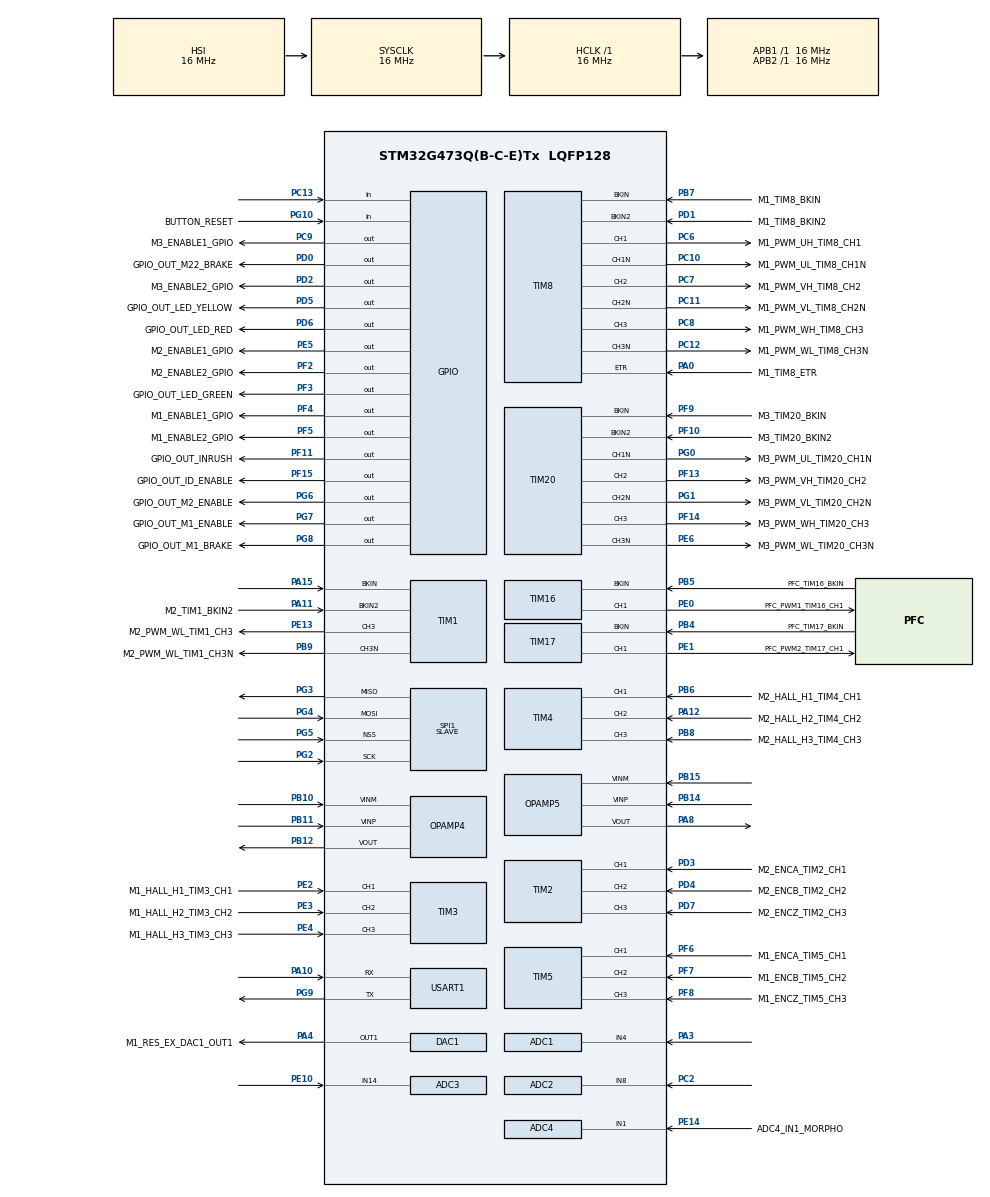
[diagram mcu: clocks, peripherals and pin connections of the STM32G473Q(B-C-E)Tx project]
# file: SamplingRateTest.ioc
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ADC1.Channel-0\#ChannelRegularConversion=ADC_CHANNEL_4
ADC1.ClockPrescaler=ADC_CLOCK_SYNC_PCLK_DIV1
ADC1.ContinuousConvMode=DISABLE
ADC1.DMAAccessModeView=ENABLE
ADC1.DMAContinuousRequests=DISABLE
ADC1.Mode=ADC_DUALMODE_REGSIMULT
ADC1.NbrOfConversionFlag=1
ADC1.OffsetNumber-0\#ChannelRegularConversion=ADC_OFFSET_NONE
ADC1.Rank-0\#ChannelRegularConversion=1
ADC1.SamplingTime-0\#ChannelRegularConversion=ADC_SAMPLETIME_2CYCLES_5
ADC1.TwoSamplingDelay=ADC_TWOSAMPLINGDELAY_12CYCLES
ADC1.master=1
ADC2.Channel-1\#ChannelRegularConversion=ADC_CHANNEL_8
ADC2.ClockPrescaler=ADC_CLOCK_SYNC_PCLK_DIV1
ADC2.ContinuousConvMode=DISABLE
ADC2.DMAAccessModeView=ENABLE
ADC2.DMAContinuousRequests=DISABLE
ADC2.EnableAnalogWatchDog3=false
ADC2.Mode=ADC_DUALMODE_REGSIMULT
ADC2.NbrOfConversion=1
ADC2.NbrOfConversionFlag=1
ADC2.OffsetNumber-1\#ChannelRegularConversion=ADC_OFFSET_NONE
ADC2.Overrun=ADC_OVR_DATA_PRESERVED
ADC2.Rank-1\#ChannelRegularConversion=1
ADC2.Resolution=ADC_RESOLUTION_12B
ADC2.SamplingTime-1\#ChannelRegularConversion=ADC_SAMPLETIME_2CYCLES_5
ADC2.TwoSamplingDelay=ADC_TWOSAMPLINGDELAY_12CYCLES
ADC3.Channel-2\#ChannelRegularConversion=ADC_CHANNEL_14
ADC3.ClockPrescaler=ADC_CLOCK_ASYNC_DIV64
ADC3.ContinuousConvMode=DISABLE
ADC3.DMAAccessModeView=ENABLE
ADC3.DMAContinuousRequests=DISABLE
ADC3.Mode=ADC_DUALMODE_REGSIMULT
ADC3.NbrOfConversionFlag=1
ADC3.OffsetNumber-2\#ChannelRegularConversion=ADC_OFFSET_NONE
ADC3.Rank-2\#ChannelRegularConversion=1
ADC3.SamplingTime-2\#ChannelRegularConversion=ADC_SAMPLETIME_2CYCLES_5
ADC3.TwoSamplingDelay=ADC_TWOSAMPLINGDELAY_12CYCLES
ADC3.master=1
ADC4.Channel-1\#ChannelRegularConversion=ADC_CHANNEL_1
ADC4.ClockPrescaler=ADC_CLOCK_ASYNC_DIV64
ADC4.DMAAccessModeView=ENABLE
ADC4.Mode=ADC_DUALMODE_REGSIMULT
ADC4.NbrOfConversionFlag=1
ADC4.OffsetNumber-1\#ChannelRegularConversion=ADC_OFFSET_NONE
ADC4.Rank-1\#ChannelRegularConversion=1
ADC4.SamplingTime-1\#ChannelRegularConversion=ADC_SAMPLETIME_2CYCLES_5
ADC4.TwoSamplingDelay=ADC_TWOSAMPLINGDELAY_12CYCLES
DAC1.DAC_Channel-DAC_OUT2_ExtAndInt=DAC_CHANNEL_2
Mcu.Family=STM32G4
Mcu.Name=STM32G473Q(B-C-E)Tx
Mcu.Package=LQFP128
NVIC.ADC1_2_IRQn=true\:1\:0\:true\:false\:true\:true\:true\:true
NVIC.PriorityGroup=NVIC_PRIORITYGROUP_4
PA0.GPIO_Label=M1_TIM8_ETR
PA0.Signal=S_TIM8_ETR
PA10.Mode=Asynchronous
PA10.Signal=USART1_RX
PA11.GPIO_Label=M2_TIM1_BKIN2
PA11.Mode=Activate-Break-Input-2
PA11.Signal=TIM1_BKIN2
PA12.GPIO_Label=M2_HALL_H2_TIM4_CH2
PA12.Signal=S_TIM4_CH2
PA13.Mode=Trace_Asynchronous_SW
PA13.Signal=SYS_JTMS-SWDIO
PA14.Mode=Trace_Asynchronous_SW
PA14.Signal=SYS_JTCK-SWCLK
PA15.Mode=Activate-Break-Input
PA15.Signal=TIM1_BKIN
PA2.GPIO_Mode=GPIO_MODE_ANALOG
PA2.GPIO_PuPd=GPIO_NOPULL
PA2.Signal=ADC1_IN3
PA3.Mode=IN4-Single-Ended
PA3.Signal=ADC1_IN4
PA4.GPIO_Label=M1_RES_EX_DAC1_OUT1
PA4.Signal=COMP_DAC11_group
PA6.GPIO_Label=M3_TEMP_ID_ADC2IN3
PA6.Signal=ADC2_IN3
PA8.Mode=Standalone
PA8.Signal=OPAMP5_VOUT
PB0.Signal=OPAMP3_VINP
PB1.Signal=OPAMP3_VOUT
PB10.Mode=Standalone
PB10.Signal=OPAMP4_VINM
PB11.Mode=Standalone
PB11.Signal=OPAMP4_VINP
PB12.Mode=Standalone
PB12.Signal=OPAMP4_VOUT
PB13.GPIO_Label=M1_VBUS_ADC3_IN5
PB13.Signal=ADC3_IN5
PB14.Mode=Standalone
PB14.Signal=OPAMP5_VINP
PB15.Mode=Standalone
PB15.Signal=OPAMP5_VINM
PB3.Mode=Trace_Asynchronous_SW
PB3.Signal=SYS_JTDO-SWO
PB4.GPIO_Label=PFC_TIM17_BKIN
PB4.Mode=Activate-Break-Input
PB4.Signal=TIM17_BKIN
PB5.GPIO_Label=PFC_TIM16_BKIN
PB5.Mode=Activate-Break-Input
PB5.Signal=TIM16_BKIN
PB6.GPIO_Label=M2_HALL_H1_TIM4_CH1
PB6.Signal=S_TIM4_CH1
PB7.GPIO_Label=M1_TIM8_BKIN
PB7.Mode=Activate-Break-Input
PB7.Signal=TIM8_BKIN
PB8-BOOT0.GPIO_Label=M2_HALL_H3_TIM4_CH3
PB8-BOOT0.Signal=S_TIM4_CH3
PB9.GPIO_Label=M2_PWM_WL_TIM1_CH3N
PB9.Mode=PWM Generation3 CH3 CH3N
PB9.Signal=TIM1_CH3N
PC0.Signal=ADC2_IN6
PC10.GPIO_Label=M1_PWM_UL_TIM8_CH1N
PC10.Mode=PWM Generation1 CH1 CH1N
PC10.Signal=TIM8_CH1N
PC11.GPIO_Label=M1_PWM_VL_TIM8_CH2N
PC11.Mode=Output Compare2 CH2 CH2N
PC11.Signal=TIM8_CH2N
PC12.GPIO_Label=M1_PWM_WL_TIM8_CH3N
PC12.Mode=Output Compare3 CH3 CH3N
PC12.Signal=TIM8_CH3N
PC13.GPIO_PuPd=GPIO_PULLUP
PC13.Signal=GPIO_Input
PC14-OSC32_IN.Mode=LSE-External-Oscillator
PC14-OSC32_IN.Signal=RCC_OSC32_IN
PC15-OSC32_OUT.Mode=LSE-External-Oscillator
PC15-OSC32_OUT.Signal=RCC_OSC32_OUT
PC2.GPIO_Mode=GPIO_MODE_ANALOG
PC2.GPIO_PuPd=GPIO_NOPULL
PC2.Mode=IN8-Single-Ended
PC2.Signal=ADC2_IN8
PC3.Signal=ADC2_IN9
PC4.GPIO_Label=M2_TEMP_ID_ADC2_IN5
PC4.Signal=ADC2_IN5
PC5.GPIO_Label=PFC_AC_ZC_ADC2_IN11
PC5.Signal=ADC2_IN11
PC6.GPIO_Label=M1_PWM_UH_TIM8_CH1
PC6.Signal=S_TIM8_CH1
PC7.GPIO_Label=M1_PWM_VH_TIM8_CH2
PC7.Signal=S_TIM8_CH2
PC8.GPIO_Label=M1_PWM_WH_TIM8_CH3
PC8.Signal=S_TIM8_CH3
PC9.GPIO_Label=M3_ENABLE1_GPIO
PC9.Signal=GPIO_Output
PD0.GPIO_Label=GPIO_OUT_M22_BRAKE
PD0.Signal=GPIO_Output
PD1.GPIO_Label=M1_TIM8_BKIN2
PD1.Mode=Activate-Break-Input-2
PD1.Signal=TIM8_BKIN2
PD2.GPIO_Label=M3_ENABLE2_GPIO
PD2.Signal=GPIO_Output
PD3.GPIO_Label=M2_ENCA_TIM2_CH1
PD3.Signal=S_TIM2_CH1
PD4.GPIO_Label=M2_ENCB_TIM2_CH2
PD4.Signal=S_TIM2_CH2
PD5.GPIO_Label=GPIO_OUT_LED_YELLOW
PD5.Signal=GPIO_Output
PD6.GPIO_Label=GPIO_OUT_LED_RED
PD6.Signal=GPIO_Output
PD7.GPIO_Label=M2_ENCZ_TIM2_CH3
PD7.Signal=S_TIM2_CH3
PE0.GPIO_Label=PFC_PWM1_TIM16_CH1
PE0.Signal=S_TIM16_CH1
PE1.GPIO_Label=PFC_PWM2_TIM17_CH1
PE1.Signal=S_TIM17_CH1
PE10.Mode=IN14-Single-Ended
PE10.Signal=ADC3_IN14
PE11.GPIO_Label=M2_PWM_VH_TIM1_CH2
PE11.Signal=S_TIM1_CH2
PE13.GPIO_Label=M2_PWM_WL_TIM1_CH3
PE13.Signal=S_TIM1_CH3
PE14.GPIO_Label=ADC4_IN1_MORPHO
PE14.Mode=IN1-Single-Ended
PE14.Signal=ADC4_IN1
PE15.GPIO_Label=M1_TEMP_ID_ADC4_IN2
PE15.Signal=ADC4_IN2
PE2.GPIO_Label=M1_HALL_H1_TIM3_CH1
PE2.Signal=S_TIM3_CH1
PE3.GPIO_Label=M1_HALL_H2_TIM3_CH2
PE3.Signal=S_TIM3_CH2
PE4.GPIO_Label=M1_HALL_H3_TIM3_CH3
PE4.Signal=S_TIM3_CH3
PE5.GPIO_Label=M2_ENABLE1_GPIO
PE5.Signal=GPIO_Output
PE6.GPIO_Label=M3_PWM_WL_TIM20_CH3N
PE6.Mode=Output Compare3 CH3 CH3N
PE6.Signal=TIM20_CH3N
PE9.GPIO_Label=M2_PWM_UH_TIM1_CH1
PE9.Signal=S_TIM1_CH1
PF0-OSC_IN.Mode=HSE-External-Clock-Source
PF0-OSC_IN.Signal=RCC_OSC_IN
PF1-OSC_OUT.GPIO_Label=ADC2_IN10_PFC_AC_V
PF1-OSC_OUT.Signal=ADC2_IN10
PF10.GPIO_Label=M3_TIM20_BKIN2
PF10.Mode=Activate-Break-Input-2
PF10.Signal=TIM20_BKIN2
PF11.GPIO_Label=GPIO_OUT_INRUSH
PF11.Signal=GPIO_Output
PF12.GPIO_Label=M3_PWM_UH_TIM20_CH1
PF12.Signal=S_TIM20_CH1
PF13.GPIO_Label=M3_PWM_VH_TIM20_CH2
PF13.Signal=S_TIM20_CH2
PF14.GPIO_Label=M3_PWM_WH_TIM20_CH3
PF14.Signal=S_TIM20_CH3
PF15.GPIO_Label=GPIO_OUT_ID_ENABLE
PF15.Signal=GPIO_Output
PF2.GPIO_Label=M2_ENABLE2_GPIO
PF2.Signal=GPIO_Output
PF3.GPIO_Label=GPIO_OUT_LED_GREEN
PF3.Signal=GPIO_Output
PF4.GPIO_Label=M1_ENABLE1_GPIO
PF4.Signal=GPIO_Output
PF5.GPIO_Label=M1_ENABLE2_GPIO
PF5.Signal=GPIO_Output
PF6.GPIO_Label=M1_ENCA_TIM5_CH1
PF6.Signal=S_TIM5_CH1
PF7.GPIO_Label=M1_ENCB_TIM5_CH2
PF7.Signal=S_TIM5_CH2
PF8.GPIO_Label=M1_ENCZ_TIM5_CH3
PF8.Signal=S_TIM5_CH3
PF9.GPIO_Label=M3_TIM20_BKIN
PF9.Mode=Activate-Break-Input
PF9.Signal=TIM20_BKIN
PG0.GPIO_Label=M3_PWM_UL_TIM20_CH1N
PG0.Mode=PWM Generation1 CH1 CH1N
PG0.Signal=TIM20_CH1N
PG1.GPIO_Label=M3_PWM_VL_TIM20_CH2N
PG1.Mode=PWM Generation2 CH2 CH2N
PG1.Signal=TIM20_CH2N
PG10-NRST.GPIO_Label=BUTTON_RESET
PG10-NRST.Signal=GPIO_Input
PG2.Mode=Full_Duplex_Slave
PG2.Signal=SPI1_SCK
PG3.Mode=Full_Duplex_Slave
PG3.Signal=SPI1_MISO
PG4.Mode=Full_Duplex_Slave
PG4.Signal=SPI1_MOSI
PG5.Mode=NSS_Signal_Hard_Input
PG5.Signal=SPI1_NSS
PG6.GPIO_Label=GPIO_OUT_M2_ENABLE
PG6.Signal=GPIO_Output
PG7.GPIO_Label=GPIO_OUT_M1_ENABLE
PG7.Signal=GPIO_Output
PG8.GPIO_Label=GPIO_OUT_M1_BRAKE
PG8.Signal=GPIO_Output
PG9.Mode=Asynchronous
PG9.Signal=USART1_TX
ProjectManager.HeapSize=0x200
ProjectManager.StackSize=0x400
ProjectManager.TargetToolchain=STM32CubeIDE
RCC.ADC12Freq_Value=16000000
RCC.ADC345Freq_Value=16000000
RCC.AHBFreq_Value=16000000
RCC.APB1Freq_Value=16000000
RCC.APB1TimFreq_Value=16000000
RCC.APB2Freq_Value=16000000
RCC.APB2TimFreq_Value=16000000
RCC.CortexFreq_Value=16000000
RCC.EXTERNAL_CLOCK_VALUE=12288000
RCC.HCLKFreq_Value=16000000
RCC.HSE_VALUE=8000000
RCC.HSI48_VALUE=48000000
RCC.HSI_VALUE=16000000
RCC.SYSCLKFreq_VALUE=16000000
RCC.USBFreq_Value=64000000
RCC.VCOOutputFreq_Value=128000000
SH.COMP_DAC11_group.0=DAC1_OUT1,DAC_OUT1_ExtAndInt
SH.S_TIM16_CH1.0=TIM16_CH1,Output Compare1 CH1
SH.S_TIM17_CH1.0=TIM17_CH1,Output Compare1 CH1
SH.S_TIM1_CH1.0=TIM1_CH1
SH.S_TIM1_CH2.0=TIM1_CH2
SH.S_TIM1_CH3.0=TIM1_CH3,PWM Generation3 CH3 CH3N
SH.S_TIM20_CH1.0=TIM20_CH1
SH.S_TIM20_CH2.0=TIM20_CH2,PWM Generation2 CH2 CH2N
SH.S_TIM20_CH3.0=TIM20_CH3,Output Compare3 CH3 CH3N
SH.S_TIM2_CH1.0=TIM2_CH1,Encoder_Interface
SH.S_TIM2_CH2.0=TIM2_CH2,Encoder_Interface
SH.S_TIM2_CH3.0=TIM2_CH3,Input_Capture3_from_TI3
SH.S_TIM3_CH1.0=TIM3_CH1,Xored_Inputs_Hall_Sensor_Interface
SH.S_TIM3_CH2.0=TIM3_CH2,Xored_Inputs_Hall_Sensor_Interface
SH.S_TIM3_CH3.0=TIM3_CH3,Xored_Inputs_Hall_Sensor_Interface
SH.S_TIM4_CH1.0=TIM4_CH1,Xored_Inputs_Hall_Sensor_Interface
SH.S_TIM4_CH2.0=TIM4_CH2,Xored_Inputs_Hall_Sensor_Interface
SH.S_TIM4_CH3.0=TIM4_CH3,Xored_Inputs_Hall_Sensor_Interface
SH.S_TIM5_CH1.0=TIM5_CH1,Encoder_Interface
SH.S_TIM5_CH2.0=TIM5_CH2,Encoder_Interface
SH.S_TIM5_CH3.0=TIM5_CH3,Input_Capture3_from_TI3
SH.S_TIM8_CH1.0=TIM8_CH1,PWM Generation1 CH1 CH1N
SH.S_TIM8_CH2.0=TIM8_CH2,Output Compare2 CH2 CH2N
SH.S_TIM8_CH3.0=TIM8_CH3,Output Compare3 CH3 CH3N
SH.S_TIM8_ETR.0=TIM8_ETR,ETR-as-clearing-source
SPI1.Direction=SPI_DIRECTION_2LINES
SPI1.Mode=SPI_MODE_SLAVE
SPI1.VirtualNSS=VM_NSSHARD
SPI1.VirtualType=VM_SLAVE
TIM1.Channel-PWM\ Generation3\ CH3\ CH3N=TIM_CHANNEL_3
TIM16.Channel=TIM_CHANNEL_1
TIM17.Channel=TIM_CHANNEL_1
TIM2.Channel-Input_Capture3_from_TI3=TIM_CHANNEL_3
TIM20.Channel-Output\ Compare3\ CH3\ CH3N=TIM_CHANNEL_3
TIM20.Channel-PWM\ Generation1\ CH1\ CH1N=TIM_CHANNEL_1
TIM20.Channel-PWM\ Generation2\ CH2\ CH2N=TIM_CHANNEL_2
TIM5.Channel-Input_Capture3_from_TI3=TIM_CHANNEL_3
TIM8.Channel-Output\ Compare2\ CH2\ CH2N=TIM_CHANNEL_2
TIM8.Channel-Output\ Compare3\ CH3\ CH3N=TIM_CHANNEL_3
TIM8.Channel-PWM\ Generation1\ CH1\ CH1N=TIM_CHANNEL_1
USART1.VirtualMode-Asynchronous=VM_ASYNC
VP_SYS_VS_DBSignals.Mode=DisableDeadBatterySignals
VP_TIM16_VS_ClockSourceINT.Mode=Enable_Timer
VP_TIM17_VS_ClockSourceINT.Mode=Enable_Timer
VP_TIM1_VS_ClockSourceITR.Mode=TriggerSource_ITR1
VP_TIM1_VS_ControllerModeTrigger.Mode=Trigger Mode
VP_TIM20_VS_ClockSourceITR.Mode=TriggerSource_ITR1
VP_TIM20_VS_ControllerModeTrigger.Mode=Trigger Mode
VP_TIM3_VS_ClockSourceINT.Mode=Internal
VP_TIM4_VS_ClockSourceINT.Mode=Internal
VP_TIM8_VS_ClockSourceITR.Mode=TriggerSource_ITR1
VP_TIM8_VS_ControllerModeTrigger.Mode=Trigger Mode
board=B-G473E-ZEST1S

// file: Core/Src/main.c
/* USER CODE BEGIN Header */
/**
  ******************************************************************************
  * @file           : main.c
  * @brief          : Main program body
  ******************************************************************************
  * @attention
  *
  * Copyright (c) 2025 STMicroelectronics.
  * All rights reserved.
  *
  * This software is licensed under terms that can be found in the LICENSE file
  * in the root directory of this software component.
  * If no LICENSE file comes with this software, it is provided AS-IS.
  *
  ******************************************************************************
  */
/* USER CODE END Header */
#include "main.h"
#include <string.h>
#include <stdio.h>

ADC_HandleTypeDef hadc1;
ADC_HandleTypeDef hadc2;
ADC_HandleTypeDef hadc3;
ADC_HandleTypeDef hadc4;

DAC_HandleTypeDef hdac1;

OPAMP_HandleTypeDef hopamp4;
OPAMP_HandleTypeDef hopamp5;

SPI_HandleTypeDef hspi1;

TIM_HandleTypeDef htim1;
TIM_HandleTypeDef htim2;
TIM_HandleTypeDef htim3;
TIM_HandleTypeDef htim4;
TIM_HandleTypeDef htim5;
TIM_HandleTypeDef htim8;
TIM_HandleTypeDef htim16;
TIM_HandleTypeDef htim17;
TIM_HandleTypeDef htim20;

UART_HandleTypeDef huart1;

void SystemClock_Config(void);
static void MX_GPIO_Init(void);
static void MX_ADC2_Init(void);
static void MX_DAC1_Init(void);
static void MX_OPAMP4_Init(void);
static void MX_OPAMP5_Init(void);
static void MX_SPI1_Init(void);
static void MX_TIM1_Init(void);
static void MX_TIM2_Init(void);
static void MX_TIM3_Init(void);
static void MX_TIM4_Init(void);
static void MX_TIM5_Init(void);
static void MX_TIM8_Init(void);
static void MX_TIM16_Init(void);
static void MX_TIM17_Init(void);
static void MX_TIM20_Init(void);
static void MX_USART1_UART_Init(void);
static void MX_ADC1_Init(void);
static void MX_ADC3_Init(void);
static void MX_ADC4_Init(void);

int main(void)
{

  /* MCU Configuration--------------------------------------------------------*/

  /* Reset of all peripherals, Initializes the Flash interface and the Systick. */
  HAL_Init();

  /* USER CODE BEGIN Init */
  uint32_t au32_initial_ticks = 0;
  uint32_t au32_end_ticks = 0;

  uint32_t value1 = 0;
  uint32_t value2 = 0;

  uint32_t realValue1 = 0;
  uint32_t realValue2 = 0;
  uint32_t realValue3 = 0;
  uint32_t realValue4 = 0;

  uint16_t filter = 3;

  uint16_t IValue;
  uint16_t QValue;

  char endMessage[200];
  /* USER CODE END Init */

  /* Configure the system clock */
  SystemClock_Config();

  /* USER CODE BEGIN SysInit */
  CoreDebug->DEMCR |= CoreDebug_DEMCR_TRCENA_Msk;
  DWT->CYCCNT = 0;
  DWT->CTRL |= DWT_CTRL_CYCCNTENA_Msk;

  /* USER CODE END SysInit */

  /* Initialize all configured peripherals */
  MX_GPIO_Init();
  MX_ADC2_Init();
  MX_DAC1_Init();
  MX_OPAMP4_Init();
  MX_OPAMP5_Init();
  MX_SPI1_Init();
  MX_TIM1_Init();
  MX_TIM2_Init();
  MX_TIM3_Init();
  MX_TIM4_Init();
  MX_TIM5_Init();
  MX_TIM8_Init();
  MX_TIM16_Init();
  MX_TIM17_Init();
  MX_TIM20_Init();
  MX_USART1_UART_Init();
  MX_ADC1_Init();
  MX_ADC3_Init();
  MX_ADC4_Init();

  /* Infinite loop */
  /* USER CODE BEGIN WHILE */
  while (1)
  {
	HAL_Delay(1000);

	au32_initial_ticks = DWT->CYCCNT;

	value1 = HAL_ADCEx_MultiModeGetValue(&hadc1);
	value2 =  HAL_ADCEx_MultiModeGetValue(&hadc3);

	realValue1 = value1 >> 16;
	realValue2 = value1 - (realValue1 << 16);

	realValue3 = value2 >> 16;
	realValue4 = value2 - (realValue2 << 16);

    IValue = realValue1 * filter - realValue2;
	QValue = realValue3 * filter - realValue4;

	realValue1 = value1 >> 16;
	realValue2 = value1 - (realValue1 << 16);

	realValue3 = value2 >> 16;
	realValue4 = value2 - (realValue2 << 16);

    IValue = realValue1 * filter - realValue2;
	QValue = realValue3 * filter - realValue4;

	realValue1 = value1 >> 16;
	realValue2 = value1 - (realValue1 << 16);

	realValue3 = value2 >> 16;
	realValue4 = value2 - (realValue2 << 16);

    IValue = realValue1 * filter - realValue2;
	QValue = realValue3 * filter - realValue4;

	realValue1 = value1 >> 16;
	realValue2 = value1 - (realValue1 << 16);

	realValue3 = value2 >> 16;
	realValue4 = value2 - (realValue2 << 16);

    IValue = realValue1 * filter - realValue2;
	QValue = realValue3 * filter - realValue4;

	realValue3 = value2 >> 16;
	realValue4 = value2 - (realValue2 << 16);

    IValue = realValue1 * filter - realValue2;
	QValue = realValue3 * filter - realValue4;

	realValue3 = value2 >> 16;
	realValue4 = value2 - (realValue2 << 16);

    IValue = realValue1 * filter - realValue2;
	QValue = realValue3 * filter - realValue4;

	realValue3 = value2 >> 16;
	realValue4 = value2 - (realValue2 << 16);

    IValue = realValue1 * filter - realValue2;
	QValue = realValue3 * filter - realValue4;

	realValue3 = value2 >> 16;
	realValue4 = value2 - (realValue2 << 16);

    IValue = realValue1 * filter - realValue2;
	QValue = realValue3 * filter - realValue4;

	realValue3 = value2 >> 16;
	realValue4 = value2 - (realValue2 << 16);

    IValue = realValue1 * filter - realValue2;
	QValue = realValue3 * filter - realValue4;

	realValue3 = value2 >> 16;
	realValue4 = value2 - (realValue2 << 16);

    IValue = realValue1 * filter - realValue2;
	QValue = realValue3 * filter - realValue4;

	realValue3 = value2 >> 16;
	realValue4 = value2 - (realValue2 << 16);

    IValue = realValue1 * filter - realValue2;
	QValue = realValue3 * filter - realValue4;

	realValue3 = value2 >> 16;
	realValue4 = value2 - (realValue2 << 16);

    IValue = realValue1 * filter - realValue2;
	QValue = realValue3 * filter - realValue4;

	realValue3 = value2 >> 16;
	realValue4 = value2 - (realValue2 << 16);

    IValue = realValue1 * filter - realValue2;
	QValue = realValue3 * filter - realValue4;

	au32_end_ticks = DWT->CYCCNT;

	sprintf(endMessage, "After starting at %lu. It took %lu clock cycles to read one cycle\r\n", au32_initial_ticks, au32_end_ticks - au32_initial_ticks);
	HAL_UART_Transmit(&huart1, (uint8_t*) endMessage, strlen(endMessage), HAL_MAX_DELAY);

	float samplingTime;
	samplingTime = (float) (au32_end_ticks - au32_initial_ticks)/HAL_RCC_GetHCLKFreq() * 1000000;

	double samplingRate;
	samplingRate = 1 / samplingTime;

	sprintf(endMessage, "It took %1.3f microseconds to read one cycle, corresponding to a sampling rate of %1.9lf MSPS\r\n", samplingTime, samplingRate);

	HAL_UART_Transmit(&huart1, (uint8_t*) endMessage, strlen(endMessage), HAL_MAX_DELAY);

    /* USER CODE END WHILE */

  }
}

void SystemClock_Config(void)
{
  RCC_OscInitTypeDef RCC_OscInitStruct = {0};
  RCC_ClkInitTypeDef RCC_ClkInitStruct = {0};

  /** Configure the main internal regulator output voltage
  */
  HAL_PWREx_ControlVoltageScaling(PWR_REGULATOR_VOLTAGE_SCALE1);

  /** Initializes the RCC Oscillators according to the specified parameters
  * in the RCC_OscInitTypeDef structure.
  */
  RCC_OscInitStruct.OscillatorType = RCC_OSCILLATORTYPE_HSI;
  RCC_OscInitStruct.HSIState = RCC_HSI_ON;
  RCC_OscInitStruct.HSICalibrationValue = RCC_HSICALIBRATION_DEFAULT;
  RCC_OscInitStruct.PLL.PLLState = RCC_PLL_NONE;
  if (HAL_RCC_OscConfig(&RCC_OscInitStruct) != HAL_OK)
  {
    Error_Handler();
  }

  /** Initializes the CPU, AHB and APB buses clocks
  */
  RCC_ClkInitStruct.ClockType = RCC_CLOCKTYPE_HCLK|RCC_CLOCKTYPE_SYSCLK
                              |RCC_CLOCKTYPE_PCLK1|RCC_CLOCKTYPE_PCLK2;
  RCC_ClkInitStruct.SYSCLKSource = RCC_SYSCLKSOURCE_HSI;
  RCC_ClkInitStruct.AHBCLKDivider = RCC_SYSCLK_DIV1;
  RCC_ClkInitStruct.APB1CLKDivider = RCC_HCLK_DIV1;
  RCC_ClkInitStruct.APB2CLKDivider = RCC_HCLK_DIV1;

  if (HAL_RCC_ClockConfig(&RCC_ClkInitStruct, FLASH_LATENCY_0) != HAL_OK)
  {
    Error_Handler();
  }
}

static void MX_ADC1_Init(void)
{

  ADC_MultiModeTypeDef multimode = {0};
  ADC_ChannelConfTypeDef sConfig = {0};

  /** Common config
  */
  hadc1.Instance = ADC1;
  hadc1.Init.ClockPrescaler = ADC_CLOCK_SYNC_PCLK_DIV1;
  hadc1.Init.Resolution = ADC_RESOLUTION_12B;
  hadc1.Init.DataAlign = ADC_DATAALIGN_RIGHT;
  hadc1.Init.GainCompensation = 0;
  hadc1.Init.ScanConvMode = ADC_SCAN_DISABLE;
  hadc1.Init.EOCSelection = ADC_EOC_SINGLE_CONV;
  hadc1.Init.LowPowerAutoWait = DISABLE;
  hadc1.Init.ContinuousConvMode = DISABLE;
  hadc1.Init.NbrOfConversion = 1;
  hadc1.Init.DiscontinuousConvMode = DISABLE;
  hadc1.Init.ExternalTrigConv = ADC_SOFTWARE_START;
  hadc1.Init.ExternalTrigConvEdge = ADC_EXTERNALTRIGCONVEDGE_NONE;
  hadc1.Init.DMAContinuousRequests = DISABLE;
  hadc1.Init.Overrun = ADC_OVR_DATA_PRESERVED;
  hadc1.Init.OversamplingMode = DISABLE;
  if (HAL_ADC_Init(&hadc1) != HAL_OK)
  {
    Error_Handler();
  }

  /** Configure the ADC multi-mode
  */
  multimode.Mode = ADC_DUALMODE_REGSIMULT;
  multimode.DMAAccessMode = ADC_DMAACCESSMODE_12_10_BITS;
  multimode.TwoSamplingDelay = ADC_TWOSAMPLINGDELAY_12CYCLES;
  if (HAL_ADCEx_MultiModeConfigChannel(&hadc1, &multimode) != HAL_OK)
  {
    Error_Handler();
  }

  /** Configure Regular Channel
  */
  sConfig.Channel = ADC_CHANNEL_4;
  sConfig.Rank = ADC_REGULAR_RANK_1;
  sConfig.SamplingTime = ADC_SAMPLETIME_2CYCLES_5;
  sConfig.SingleDiff = ADC_SINGLE_ENDED;
  sConfig.OffsetNumber = ADC_OFFSET_NONE;
  sConfig.Offset = 0;
  if (HAL_ADC_ConfigChannel(&hadc1, &sConfig) != HAL_OK)
  {
    Error_Handler();
  }

}

static void MX_ADC2_Init(void)
{

  ADC_ChannelConfTypeDef sConfig = {0};

  /** Common config
  */
  hadc2.Instance = ADC2;
  hadc2.Init.ClockPrescaler = ADC_CLOCK_SYNC_PCLK_DIV1;
  hadc2.Init.Resolution = ADC_RESOLUTION_12B;
  hadc2.Init.DataAlign = ADC_DATAALIGN_RIGHT;
  hadc2.Init.GainCompensation = 0;
  hadc2.Init.ScanConvMode = ADC_SCAN_DISABLE;
  hadc2.Init.EOCSelection = ADC_EOC_SINGLE_CONV;
  hadc2.Init.LowPowerAutoWait = DISABLE;
  hadc2.Init.ContinuousConvMode = DISABLE;
  hadc2.Init.NbrOfConversion = 1;
  hadc2.Init.DiscontinuousConvMode = DISABLE;
  hadc2.Init.DMAContinuousRequests = DISABLE;
  hadc2.Init.Overrun = ADC_OVR_DATA_PRESERVED;
  hadc2.Init.OversamplingMode = DISABLE;
  if (HAL_ADC_Init(&hadc2) != HAL_OK)
  {
    Error_Handler();
  }

  /** Configure Regular Channel
  */
  sConfig.Channel = ADC_CHANNEL_8;
  sConfig.Rank = ADC_REGULAR_RANK_1;
  sConfig.SamplingTime = ADC_SAMPLETIME_2CYCLES_5;
  sConfig.SingleDiff = ADC_SINGLE_ENDED;
  sConfig.OffsetNumber = ADC_OFFSET_NONE;
  sConfig.Offset = 0;
  if (HAL_ADC_ConfigChannel(&hadc2, &sConfig) != HAL_OK)
  {
    Error_Handler();
  }

}

static void MX_ADC3_Init(void)
{

  ADC_MultiModeTypeDef multimode = {0};
  ADC_ChannelConfTypeDef sConfig = {0};

  /** Common config
  */
  hadc3.Instance = ADC3;
  hadc3.Init.ClockPrescaler = ADC_CLOCK_ASYNC_DIV64;
  hadc3.Init.Resolution = ADC_RESOLUTION_12B;
  hadc3.Init.DataAlign = ADC_DATAALIGN_RIGHT;
  hadc3.Init.GainCompensation = 0;
  hadc3.Init.ScanConvMode = ADC_SCAN_DISABLE;
  hadc3.Init.EOCSelection = ADC_EOC_SINGLE_CONV;
  hadc3.Init.LowPowerAutoWait = DISABLE;
  hadc3.Init.ContinuousConvMode = DISABLE;
  hadc3.Init.NbrOfConversion = 1;
  hadc3.Init.DiscontinuousConvMode = DISABLE;
  hadc3.Init.ExternalTrigConv = ADC_SOFTWARE_START;
  hadc3.Init.ExternalTrigConvEdge = ADC_EXTERNALTRIGCONVEDGE_NONE;
  hadc3.Init.DMAContinuousRequests = DISABLE;
  hadc3.Init.Overrun = ADC_OVR_DATA_PRESERVED;
  hadc3.Init.OversamplingMode = DISABLE;
  if (HAL_ADC_Init(&hadc3) != HAL_OK)
  {
    Error_Handler();
  }

  /** Configure the ADC multi-mode
  */
  multimode.Mode = ADC_DUALMODE_REGSIMULT;
  multimode.DMAAccessMode = ADC_DMAACCESSMODE_12_10_BITS;
  multimode.TwoSamplingDelay = ADC_TWOSAMPLINGDELAY_12CYCLES;
  if (HAL_ADCEx_MultiModeConfigChannel(&hadc3, &multimode) != HAL_OK)
  {
    Error_Handler();
  }

  /** Configure Regular Channel
  */
  sConfig.Channel = ADC_CHANNEL_14;
  sConfig.Rank = ADC_REGULAR_RANK_1;
  sConfig.SamplingTime = ADC_SAMPLETIME_2CYCLES_5;
  sConfig.SingleDiff = ADC_SINGLE_ENDED;
  sConfig.OffsetNumber = ADC_OFFSET_NONE;
  sConfig.Offset = 0;
  if (HAL_ADC_ConfigChannel(&hadc3, &sConfig) != HAL_OK)
  {
    Error_Handler();
  }

}

static void MX_ADC4_Init(void)
{

  ADC_ChannelConfTypeDef sConfig = {0};

  /** Common config
  */
  hadc4.Instance = ADC4;
  hadc4.Init.ClockPrescaler = ADC_CLOCK_ASYNC_DIV64;
  hadc4.Init.Resolution = ADC_RESOLUTION_12B;
  hadc4.Init.DataAlign = ADC_DATAALIGN_RIGHT;
  hadc4.Init.GainCompensation = 0;
  hadc4.Init.ScanConvMode = ADC_SCAN_DISABLE;
  hadc4.Init.EOCSelection = ADC_EOC_SINGLE_CONV;
  hadc4.Init.LowPowerAutoWait = DISABLE;
  hadc4.Init.ContinuousConvMode = DISABLE;
  hadc4.Init.NbrOfConversion = 1;
  hadc4.Init.DiscontinuousConvMode = DISABLE;
  hadc4.Init.DMAContinuousRequests = DISABLE;
  hadc4.Init.Overrun = ADC_OVR_DATA_PRESERVED;
  hadc4.Init.OversamplingMode = DISABLE;
  if (HAL_ADC_Init(&hadc4) != HAL_OK)
  {
    Error_Handler();
  }

  /** Configure Regular Channel
  */
  sConfig.Channel = ADC_CHANNEL_1;
  sConfig.Rank = ADC_REGULAR_RANK_1;
  sConfig.SamplingTime = ADC_SAMPLETIME_2CYCLES_5;
  sConfig.SingleDiff = ADC_SINGLE_ENDED;
  sConfig.OffsetNumber = ADC_OFFSET_NONE;
  sConfig.Offset = 0;
  if (HAL_ADC_ConfigChannel(&hadc4, &sConfig) != HAL_OK)
  {
    Error_Handler();
  }

}

static void MX_DAC1_Init(void)
{

  DAC_ChannelConfTypeDef sConfig = {0};

  /** DAC Initialization
  */
  hdac1.Instance = DAC1;
  if (HAL_DAC_Init(&hdac1) != HAL_OK)
  {
    Error_Handler();
  }

  /** DAC channel OUT1 config
  */
  sConfig.DAC_HighFrequency = DAC_HIGH_FREQUENCY_INTERFACE_MODE_AUTOMATIC;
  sConfig.DAC_DMADoubleDataMode = DISABLE;
  sConfig.DAC_SignedFormat = DISABLE;
  sConfig.DAC_SampleAndHold = DAC_SAMPLEANDHOLD_DISABLE;
  sConfig.DAC_Trigger = DAC_TRIGGER_NONE;
  sConfig.DAC_Trigger2 = DAC_TRIGGER_NONE;
  sConfig.DAC_OutputBuffer = DAC_OUTPUTBUFFER_ENABLE;
  sConfig.DAC_ConnectOnChipPeripheral = DAC_CHIPCONNECT_BOTH;
  sConfig.DAC_UserTrimming = DAC_TRIMMING_FACTORY;
  if (HAL_DAC_ConfigChannel(&hdac1, &sConfig, DAC_CHANNEL_1) != HAL_OK)
  {
    Error_Handler();
  }

}

static void MX_OPAMP4_Init(void)
{

  hopamp4.Instance = OPAMP4;
  hopamp4.Init.PowerMode = OPAMP_POWERMODE_NORMALSPEED;
  hopamp4.Init.Mode = OPAMP_STANDALONE_MODE;
  hopamp4.Init.InvertingInput = OPAMP_INVERTINGINPUT_IO0;
  hopamp4.Init.NonInvertingInput = OPAMP_NONINVERTINGINPUT_IO2;
  hopamp4.Init.InternalOutput = DISABLE;
  hopamp4.Init.TimerControlledMuxmode = OPAMP_TIMERCONTROLLEDMUXMODE_DISABLE;
  hopamp4.Init.UserTrimming = OPAMP_TRIMMING_FACTORY;
  if (HAL_OPAMP_Init(&hopamp4) != HAL_OK)
  {
    Error_Handler();
  }

}

static void MX_OPAMP5_Init(void)
{

  hopamp5.Instance = OPAMP5;
  hopamp5.Init.PowerMode = OPAMP_POWERMODE_NORMALSPEED;
  hopamp5.Init.Mode = OPAMP_STANDALONE_MODE;
  hopamp5.Init.InvertingInput = OPAMP_INVERTINGINPUT_IO0;
  hopamp5.Init.NonInvertingInput = OPAMP_NONINVERTINGINPUT_IO0;
  hopamp5.Init.InternalOutput = DISABLE;
  hopamp5.Init.TimerControlledMuxmode = OPAMP_TIMERCONTROLLEDMUXMODE_DISABLE;
  hopamp5.Init.UserTrimming = OPAMP_TRIMMING_FACTORY;
  if (HAL_OPAMP_Init(&hopamp5) != HAL_OK)
  {
    Error_Handler();
  }

}

static void MX_SPI1_Init(void)
{

  /* SPI1 parameter configuration*/
  hspi1.Instance = SPI1;
  hspi1.Init.Mode = SPI_MODE_SLAVE;
  hspi1.Init.Direction = SPI_DIRECTION_2LINES;
  hspi1.Init.DataSize = SPI_DATASIZE_4BIT;
  hspi1.Init.CLKPolarity = SPI_POLARITY_LOW;
  hspi1.Init.CLKPhase = SPI_PHASE_1EDGE;
  hspi1.Init.NSS = SPI_NSS_HARD_INPUT;
  hspi1.Init.FirstBit = SPI_FIRSTBIT_MSB;
  hspi1.Init.TIMode = SPI_TIMODE_DISABLE;
  hspi1.Init.CRCCalculation = SPI_CRCCALCULATION_DISABLE;
  hspi1.Init.CRCPolynomial = 7;
  hspi1.Init.CRCLength = SPI_CRC_LENGTH_DATASIZE;
  hspi1.Init.NSSPMode = SPI_NSS_PULSE_DISABLE;
  if (HAL_SPI_Init(&hspi1) != HAL_OK)
  {
    Error_Handler();
  }

}

static void MX_TIM1_Init(void)
{

  TIM_SlaveConfigTypeDef sSlaveConfig = {0};
  TIM_MasterConfigTypeDef sMasterConfig = {0};
  TIMEx_BreakInputConfigTypeDef sBreakInputConfig = {0};
  TIM_OC_InitTypeDef sConfigOC = {0};
  TIM_BreakDeadTimeConfigTypeDef sBreakDeadTimeConfig = {0};

  htim1.Instance = TIM1;
  htim1.Init.Prescaler = 0;
  htim1.Init.CounterMode = TIM_COUNTERMODE_UP;
  htim1.Init.Period = 65535;
  htim1.Init.ClockDivision = TIM_CLOCKDIVISION_DIV1;
  htim1.Init.RepetitionCounter = 0;
  htim1.Init.AutoReloadPreload = TIM_AUTORELOAD_PRELOAD_DISABLE;
  if (HAL_TIM_Base_Init(&htim1) != HAL_OK)
  {
    Error_Handler();
  }
  if (HAL_TIM_PWM_Init(&htim1) != HAL_OK)
  {
    Error_Handler();
  }
  sSlaveConfig.SlaveMode = TIM_SLAVEMODE_TRIGGER;
  sSlaveConfig.InputTrigger = TIM_TS_ITR1;
  if (HAL_TIM_SlaveConfigSynchro(&htim1, &sSlaveConfig) != HAL_OK)
  {
    Error_Handler();
  }
  sMasterConfig.MasterOutputTrigger = TIM_TRGO_RESET;
  sMasterConfig.MasterOutputTrigger2 = TIM_TRGO2_RESET;
  sMasterConfig.MasterSlaveMode = TIM_MASTERSLAVEMODE_DISABLE;
  if (HAL_TIMEx_MasterConfigSynchronization(&htim1, &sMasterConfig) != HAL_OK)
  {
    Error_Handler();
  }
  sBreakInputConfig.Source = TIM_BREAKINPUTSOURCE_BKIN;
  sBreakInputConfig.Enable = TIM_BREAKINPUTSOURCE_ENABLE;
  sBreakInputConfig.Polarity = TIM_BREAKINPUTSOURCE_POLARITY_HIGH;
  if (HAL_TIMEx_ConfigBreakInput(&htim1, TIM_BREAKINPUT_BRK, &sBreakInputConfig) != HAL_OK)
  {
    Error_Handler();
  }
  if (HAL_TIMEx_ConfigBreakInput(&htim1, TIM_BREAKINPUT_BRK2, &sBreakInputConfig) != HAL_OK)
  {
    Error_Handler();
  }
  sConfigOC.OCMode = TIM_OCMODE_PWM1;
  sConfigOC.Pulse = 0;
  sConfigOC.OCPolarity = TIM_OCPOLARITY_HIGH;
  sConfigOC.OCNPolarity = TIM_OCNPOLARITY_HIGH;
  sConfigOC.OCFastMode = TIM_OCFAST_DISABLE;
  sConfigOC.OCIdleState = TIM_OCIDLESTATE_RESET;
  sConfigOC.OCNIdleState = TIM_OCNIDLESTATE_RESET;
  if (HAL_TIM_PWM_ConfigChannel(&htim1, &sConfigOC, TIM_CHANNEL_3) != HAL_OK)
  {
    Error_Handler();
  }
  sBreakDeadTimeConfig.OffStateRunMode = TIM_OSSR_ENABLE;
  sBreakDeadTimeConfig.OffStateIDLEMode = TIM_OSSI_ENABLE;
  sBreakDeadTimeConfig.LockLevel = TIM_LOCKLEVEL_OFF;
  sBreakDeadTimeConfig.DeadTime = 0;
  sBreakDeadTimeConfig.BreakState = TIM_BREAK_ENABLE;
  sBreakDeadTimeConfig.BreakPolarity = TIM_BREAKPOLARITY_HIGH;
  sBreakDeadTimeConfig.BreakFilter = 0;
  sBreakDeadTimeConfig.BreakAFMode = TIM_BREAK_AFMODE_INPUT;
  sBreakDeadTimeConfig.Break2State = TIM_BREAK2_ENABLE;
  sBreakDeadTimeConfig.Break2Polarity = TIM_BREAK2POLARITY_HIGH;
  sBreakDeadTimeConfig.Break2Filter = 0;
  sBreakDeadTimeConfig.Break2AFMode = TIM_BREAK_AFMODE_INPUT;
  sBreakDeadTimeConfig.AutomaticOutput = TIM_AUTOMATICOUTPUT_DISABLE;
  if (HAL_TIMEx_ConfigBreakDeadTime(&htim1, &sBreakDeadTimeConfig) != HAL_OK)
  {
    Error_Handler();
  }
  HAL_TIM_MspPostInit(&htim1);

}

static void MX_TIM2_Init(void)
{

  TIM_Encoder_InitTypeDef sConfig = {0};
  TIM_MasterConfigTypeDef sMasterConfig = {0};
  TIM_IC_InitTypeDef sConfigIC = {0};

  htim2.Instance = TIM2;
  htim2.Init.Prescaler = 0;
  htim2.Init.CounterMode = TIM_COUNTERMODE_UP;
  htim2.Init.Period = 4294967295;
  htim2.Init.ClockDivision = TIM_CLOCKDIVISION_DIV1;
  htim2.Init.AutoReloadPreload = TIM_AUTORELOAD_PRELOAD_DISABLE;
  if (HAL_TIM_IC_Init(&htim2) != HAL_OK)
  {
    Error_Handler();
  }
  sConfig.EncoderMode = TIM_ENCODERMODE_TI1;
  sConfig.IC1Polarity = TIM_ICPOLARITY_RISING;
  sConfig.IC1Selection = TIM_ICSELECTION_DIRECTTI;
  sConfig.IC1Prescaler = TIM_ICPSC_DIV1;
  sConfig.IC1Filter = 0;
  sConfig.IC2Polarity = TIM_ICPOLARITY_RISING;
  sConfig.IC2Selection = TIM_ICSELECTION_DIRECTTI;
  sConfig.IC2Prescaler = TIM_ICPSC_DIV1;
  sConfig.IC2Filter = 0;
  if (HAL_TIM_Encoder_Init(&htim2, &sConfig) != HAL_OK)
  {
    Error_Handler();
  }
  sMasterConfig.MasterOutputTrigger = TIM_TRGO_RESET;
  sMasterConfig.MasterSlaveMode = TIM_MASTERSLAVEMODE_DISABLE;
  if (HAL_TIMEx_MasterConfigSynchronization(&htim2, &sMasterConfig) != HAL_OK)
  {
    Error_Handler();
  }
  sConfigIC.ICPolarity = TIM_INPUTCHANNELPOLARITY_RISING;
  sConfigIC.ICSelection = TIM_ICSELECTION_DIRECTTI;
  sConfigIC.ICPrescaler = TIM_ICPSC_DIV1;
  sConfigIC.ICFilter = 0;
  if (HAL_TIM_IC_ConfigChannel(&htim2, &sConfigIC, TIM_CHANNEL_3) != HAL_OK)
  {
    Error_Handler();
  }

}

static void MX_TIM3_Init(void)
{

  TIM_ClockConfigTypeDef sClockSourceConfig = {0};
  TIM_HallSensor_InitTypeDef sConfig = {0};
  TIM_MasterConfigTypeDef sMasterConfig = {0};

  htim3.Instance = TIM3;
  htim3.Init.Prescaler = 0;
  htim3.Init.CounterMode = TIM_COUNTERMODE_UP;
  htim3.Init.Period = 65535;
  htim3.Init.ClockDivision = TIM_CLOCKDIVISION_DIV1;
  htim3.Init.AutoReloadPreload = TIM_AUTORELOAD_PRELOAD_DISABLE;
  if (HAL_TIM_Base_Init(&htim3) != HAL_OK)
  {
    Error_Handler();
  }
  sClockSourceConfig.ClockSource = TIM_CLOCKSOURCE_INTERNAL;
  if (HAL_TIM_ConfigClockSource(&htim3, &sClockSourceConfig) != HAL_OK)
  {
    Error_Handler();
  }
  sConfig.IC1Polarity = TIM_ICPOLARITY_RISING;
  sConfig.IC1Prescaler = TIM_ICPSC_DIV1;
  sConfig.IC1Filter = 0;
  sConfig.Commutation_Delay = 0;
  if (HAL_TIMEx_HallSensor_Init(&htim3, &sConfig) != HAL_OK)
  {
    Error_Handler();
  }
  sMasterConfig.MasterOutputTrigger = TIM_TRGO_OC2REF;
  sMasterConfig.MasterSlaveMode = TIM_MASTERSLAVEMODE_DISABLE;
  if (HAL_TIMEx_MasterConfigSynchronization(&htim3, &sMasterConfig) != HAL_OK)
  {
    Error_Handler();
  }

}

static void MX_TIM4_Init(void)
{

  TIM_ClockConfigTypeDef sClockSourceConfig = {0};
  TIM_HallSensor_InitTypeDef sConfig = {0};
  TIM_MasterConfigTypeDef sMasterConfig = {0};

  htim4.Instance = TIM4;
  htim4.Init.Prescaler = 0;
  htim4.Init.CounterMode = TIM_COUNTERMODE_UP;
  htim4.Init.Period = 65535;
  htim4.Init.ClockDivision = TIM_CLOCKDIVISION_DIV1;
  htim4.Init.AutoReloadPreload = TIM_AUTORELOAD_PRELOAD_DISABLE;
  if (HAL_TIM_Base_Init(&htim4) != HAL_OK)
  {
    Error_Handler();
  }
  sClockSourceConfig.ClockSource = TIM_CLOCKSOURCE_INTERNAL;
  if (HAL_TIM_ConfigClockSource(&htim4, &sClockSourceConfig) != HAL_OK)
  {
    Error_Handler();
  }
  sConfig.IC1Polarity = TIM_ICPOLARITY_RISING;
  sConfig.IC1Prescaler = TIM_ICPSC_DIV1;
  sConfig.IC1Filter = 0;
  sConfig.Commutation_Delay = 0;
  if (HAL_TIMEx_HallSensor_Init(&htim4, &sConfig) != HAL_OK)
  {
    Error_Handler();
  }
  sMasterConfig.MasterOutputTrigger = TIM_TRGO_OC2REF;
  sMasterConfig.MasterSlaveMode = TIM_MASTERSLAVEMODE_DISABLE;
  if (HAL_TIMEx_MasterConfigSynchronization(&htim4, &sMasterConfig) != HAL_OK)
  {
    Error_Handler();
  }

}

static void MX_TIM5_Init(void)
{

  TIM_Encoder_InitTypeDef sConfig = {0};
  TIM_MasterConfigTypeDef sMasterConfig = {0};
  TIM_IC_InitTypeDef sConfigIC = {0};

  htim5.Instance = TIM5;
  htim5.Init.Prescaler = 0;
  htim5.Init.CounterMode = TIM_COUNTERMODE_UP;
  htim5.Init.Period = 4294967295;
  htim5.Init.ClockDivision = TIM_CLOCKDIVISION_DIV1;
  htim5.Init.AutoReloadPreload = TIM_AUTORELOAD_PRELOAD_DISABLE;
  if (HAL_TIM_IC_Init(&htim5) != HAL_OK)
  {
    Error_Handler();
  }
  sConfig.EncoderMode = TIM_ENCODERMODE_TI1;
  sConfig.IC1Polarity = TIM_ICPOLARITY_RISING;
  sConfig.IC1Selection = TIM_ICSELECTION_DIRECTTI;
  sConfig.IC1Prescaler = TIM_ICPSC_DIV1;
  sConfig.IC1Filter = 0;
  sConfig.IC2Polarity = TIM_ICPOLARITY_RISING;
  sConfig.IC2Selection = TIM_ICSELECTION_DIRECTTI;
  sConfig.IC2Prescaler = TIM_ICPSC_DIV1;
  sConfig.IC2Filter = 0;
  if (HAL_TIM_Encoder_Init(&htim5, &sConfig) != HAL_OK)
  {
    Error_Handler();
  }
  sMasterConfig.MasterOutputTrigger = TIM_TRGO_RESET;
  sMasterConfig.MasterSlaveMode = TIM_MASTERSLAVEMODE_DISABLE;
  if (HAL_TIMEx_MasterConfigSynchronization(&htim5, &sMasterConfig) != HAL_OK)
  {
    Error_Handler();
  }
  sConfigIC.ICPolarity = TIM_INPUTCHANNELPOLARITY_RISING;
  sConfigIC.ICSelection = TIM_ICSELECTION_DIRECTTI;
  sConfigIC.ICPrescaler = TIM_ICPSC_DIV1;
  sConfigIC.ICFilter = 0;
  if (HAL_TIM_IC_ConfigChannel(&htim5, &sConfigIC, TIM_CHANNEL_3) != HAL_OK)
  {
    Error_Handler();
  }

}

static void MX_TIM8_Init(void)
{

  TIM_SlaveConfigTypeDef sSlaveConfig = {0};
  TIM_MasterConfigTypeDef sMasterConfig = {0};
  TIMEx_BreakInputConfigTypeDef sBreakInputConfig = {0};
  TIM_OC_InitTypeDef sConfigOC = {0};
  TIM_BreakDeadTimeConfigTypeDef sBreakDeadTimeConfig = {0};

  htim8.Instance = TIM8;
  htim8.Init.Prescaler = 0;
  htim8.Init.CounterMode = TIM_COUNTERMODE_UP;
  htim8.Init.Period = 65535;
  htim8.Init.ClockDivision = TIM_CLOCKDIVISION_DIV1;
  htim8.Init.RepetitionCounter = 0;
  htim8.Init.AutoReloadPreload = TIM_AUTORELOAD_PRELOAD_DISABLE;
  if (HAL_TIM_Base_Init(&htim8) != HAL_OK)
  {
    Error_Handler();
  }
  if (HAL_TIM_PWM_Init(&htim8) != HAL_OK)
  {
    Error_Handler();
  }
  if (HAL_TIM_OC_Init(&htim8) != HAL_OK)
  {
    Error_Handler();
  }
  sSlaveConfig.SlaveMode = TIM_SLAVEMODE_TRIGGER;
  sSlaveConfig.InputTrigger = TIM_TS_ITR1;
  if (HAL_TIM_SlaveConfigSynchro(&htim8, &sSlaveConfig) != HAL_OK)
  {
    Error_Handler();
  }
  sMasterConfig.MasterOutputTrigger = TIM_TRGO_RESET;
  sMasterConfig.MasterOutputTrigger2 = TIM_TRGO2_RESET;
  sMasterConfig.MasterSlaveMode = TIM_MASTERSLAVEMODE_DISABLE;
  if (HAL_TIMEx_MasterConfigSynchronization(&htim8, &sMasterConfig) != HAL_OK)
  {
    Error_Handler();
  }
  sBreakInputConfig.Source = TIM_BREAKINPUTSOURCE_BKIN;
  sBreakInputConfig.Enable = TIM_BREAKINPUTSOURCE_ENABLE;
  sBreakInputConfig.Polarity = TIM_BREAKINPUTSOURCE_POLARITY_HIGH;
  if (HAL_TIMEx_ConfigBreakInput(&htim8, TIM_BREAKINPUT_BRK, &sBreakInputConfig) != HAL_OK)
  {
    Error_Handler();
  }
  if (HAL_TIMEx_ConfigBreakInput(&htim8, TIM_BREAKINPUT_BRK2, &sBreakInputConfig) != HAL_OK)
  {
    Error_Handler();
  }
  sConfigOC.OCMode = TIM_OCMODE_PWM1;
  sConfigOC.Pulse = 0;
  sConfigOC.OCPolarity = TIM_OCPOLARITY_HIGH;
  sConfigOC.OCNPolarity = TIM_OCNPOLARITY_HIGH;
  sConfigOC.OCFastMode = TIM_OCFAST_DISABLE;
  sConfigOC.OCIdleState = TIM_OCIDLESTATE_RESET;
  sConfigOC.OCNIdleState = TIM_OCNIDLESTATE_RESET;
  if (HAL_TIM_PWM_ConfigChannel(&htim8, &sConfigOC, TIM_CHANNEL_1) != HAL_OK)
  {
    Error_Handler();
  }
  sConfigOC.OCMode = TIM_OCMODE_TIMING;
  if (HAL_TIM_OC_ConfigChannel(&htim8, &sConfigOC, TIM_CHANNEL_2) != HAL_OK)
  {
    Error_Handler();
  }
  if (HAL_TIM_OC_ConfigChannel(&htim8, &sConfigOC, TIM_CHANNEL_3) != HAL_OK)
  {
    Error_Handler();
  }
  sBreakDeadTimeConfig.OffStateRunMode = TIM_OSSR_ENABLE;
  sBreakDeadTimeConfig.OffStateIDLEMode = TIM_OSSI_ENABLE;
  sBreakDeadTimeConfig.LockLevel = TIM_LOCKLEVEL_OFF;
  sBreakDeadTimeConfig.DeadTime = 0;
  sBreakDeadTimeConfig.BreakState = TIM_BREAK_ENABLE;
  sBreakDeadTimeConfig.BreakPolarity = TIM_BREAKPOLARITY_HIGH;
  sBreakDeadTimeConfig.BreakFilter = 0;
  sBreakDeadTimeConfig.BreakAFMode = TIM_BREAK_AFMODE_INPUT;
  sBreakDeadTimeConfig.Break2State = TIM_BREAK2_ENABLE;
  sBreakDeadTimeConfig.Break2Polarity = TIM_BREAK2POLARITY_HIGH;
  sBreakDeadTimeConfig.Break2Filter = 0;
  sBreakDeadTimeConfig.Break2AFMode = TIM_BREAK_AFMODE_INPUT;
  sBreakDeadTimeConfig.AutomaticOutput = TIM_AUTOMATICOUTPUT_DISABLE;
  if (HAL_TIMEx_ConfigBreakDeadTime(&htim8, &sBreakDeadTimeConfig) != HAL_OK)
  {
    Error_Handler();
  }
  HAL_TIM_MspPostInit(&htim8);

}

static void MX_TIM16_Init(void)
{

  TIMEx_BreakInputConfigTypeDef sBreakInputConfig = {0};
  TIM_OC_InitTypeDef sConfigOC = {0};
  TIM_BreakDeadTimeConfigTypeDef sBreakDeadTimeConfig = {0};

  htim16.Instance = TIM16;
  htim16.Init.Prescaler = 0;
  htim16.Init.CounterMode = TIM_COUNTERMODE_UP;
  htim16.Init.Period = 65535;
  htim16.Init.ClockDivision = TIM_CLOCKDIVISION_DIV1;
  htim16.Init.RepetitionCounter = 0;
  htim16.Init.AutoReloadPreload = TIM_AUTORELOAD_PRELOAD_DISABLE;
  if (HAL_TIM_Base_Init(&htim16) != HAL_OK)
  {
    Error_Handler();
  }
  if (HAL_TIM_OC_Init(&htim16) != HAL_OK)
  {
    Error_Handler();
  }
  sBreakInputConfig.Source = TIM_BREAKINPUTSOURCE_BKIN;
  sBreakInputConfig.Enable = TIM_BREAKINPUTSOURCE_ENABLE;
  sBreakInputConfig.Polarity = TIM_BREAKINPUTSOURCE_POLARITY_HIGH;
  if (HAL_TIMEx_ConfigBreakInput(&htim16, TIM_BREAKINPUT_BRK, &sBreakInputConfig) != HAL_OK)
  {
    Error_Handler();
  }
  sConfigOC.OCMode = TIM_OCMODE_TIMING;
  sConfigOC.Pulse = 0;
  sConfigOC.OCPolarity = TIM_OCPOLARITY_HIGH;
  sConfigOC.OCNPolarity = TIM_OCNPOLARITY_HIGH;
  sConfigOC.OCFastMode = TIM_OCFAST_DISABLE;
  sConfigOC.OCIdleState = TIM_OCIDLESTATE_RESET;
  sConfigOC.OCNIdleState = TIM_OCNIDLESTATE_RESET;
  if (HAL_TIM_OC_ConfigChannel(&htim16, &sConfigOC, TIM_CHANNEL_1) != HAL_OK)
  {
    Error_Handler();
  }
  sBreakDeadTimeConfig.OffStateRunMode = TIM_OSSR_DISABLE;
  sBreakDeadTimeConfig.OffStateIDLEMode = TIM_OSSI_DISABLE;
  sBreakDeadTimeConfig.LockLevel = TIM_LOCKLEVEL_OFF;
  sBreakDeadTimeConfig.DeadTime = 0;
  sBreakDeadTimeConfig.BreakState = TIM_BREAK_ENABLE;
  sBreakDeadTimeConfig.BreakPolarity = TIM_BREAKPOLARITY_HIGH;
  sBreakDeadTimeConfig.BreakFilter = 0;
  sBreakDeadTimeConfig.AutomaticOutput = TIM_AUTOMATICOUTPUT_DISABLE;
  if (HAL_TIMEx_ConfigBreakDeadTime(&htim16, &sBreakDeadTimeConfig) != HAL_OK)
  {
    Error_Handler();
  }
  HAL_TIM_MspPostInit(&htim16);

}

static void MX_TIM17_Init(void)
{

  TIMEx_BreakInputConfigTypeDef sBreakInputConfig = {0};
  TIM_OC_InitTypeDef sConfigOC = {0};
  TIM_BreakDeadTimeConfigTypeDef sBreakDeadTimeConfig = {0};

  htim17.Instance = TIM17;
  htim17.Init.Prescaler = 0;
  htim17.Init.CounterMode = TIM_COUNTERMODE_UP;
  htim17.Init.Period = 65535;
  htim17.Init.ClockDivision = TIM_CLOCKDIVISION_DIV1;
  htim17.Init.RepetitionCounter = 0;
  htim17.Init.AutoReloadPreload = TIM_AUTORELOAD_PRELOAD_DISABLE;
  if (HAL_TIM_Base_Init(&htim17) != HAL_OK)
  {
    Error_Handler();
  }
  if (HAL_TIM_OC_Init(&htim17) != HAL_OK)
  {
    Error_Handler();
  }
  sBreakInputConfig.Source = TIM_BREAKINPUTSOURCE_BKIN;
  sBreakInputConfig.Enable = TIM_BREAKINPUTSOURCE_ENABLE;
  sBreakInputConfig.Polarity = TIM_BREAKINPUTSOURCE_POLARITY_HIGH;
  if (HAL_TIMEx_ConfigBreakInput(&htim17, TIM_BREAKINPUT_BRK, &sBreakInputConfig) != HAL_OK)
  {
    Error_Handler();
  }
  sConfigOC.OCMode = TIM_OCMODE_TIMING;
  sConfigOC.Pulse = 0;
  sConfigOC.OCPolarity = TIM_OCPOLARITY_HIGH;
  sConfigOC.OCNPolarity = TIM_OCNPOLARITY_HIGH;
  sConfigOC.OCFastMode = TIM_OCFAST_DISABLE;
  sConfigOC.OCIdleState = TIM_OCIDLESTATE_RESET;
  sConfigOC.OCNIdleState = TIM_OCNIDLESTATE_RESET;
  if (HAL_TIM_OC_ConfigChannel(&htim17, &sConfigOC, TIM_CHANNEL_1) != HAL_OK)
  {
    Error_Handler();
  }
  sBreakDeadTimeConfig.OffStateRunMode = TIM_OSSR_DISABLE;
  sBreakDeadTimeConfig.OffStateIDLEMode = TIM_OSSI_DISABLE;
  sBreakDeadTimeConfig.LockLevel = TIM_LOCKLEVEL_OFF;
  sBreakDeadTimeConfig.DeadTime = 0;
  sBreakDeadTimeConfig.BreakState = TIM_BREAK_ENABLE;
  sBreakDeadTimeConfig.BreakPolarity = TIM_BREAKPOLARITY_HIGH;
  sBreakDeadTimeConfig.BreakFilter = 0;
  sBreakDeadTimeConfig.AutomaticOutput = TIM_AUTOMATICOUTPUT_DISABLE;
  if (HAL_TIMEx_ConfigBreakDeadTime(&htim17, &sBreakDeadTimeConfig) != HAL_OK)
  {
    Error_Handler();
  }
  HAL_TIM_MspPostInit(&htim17);

}

static void MX_TIM20_Init(void)
{

  TIM_SlaveConfigTypeDef sSlaveConfig = {0};
  TIM_MasterConfigTypeDef sMasterConfig = {0};
  TIMEx_BreakInputConfigTypeDef sBreakInputConfig = {0};
  TIM_OC_InitTypeDef sConfigOC = {0};
  TIM_BreakDeadTimeConfigTypeDef sBreakDeadTimeConfig = {0};

  htim20.Instance = TIM20;
  htim20.Init.Prescaler = 0;
  htim20.Init.CounterMode = TIM_COUNTERMODE_UP;
  htim20.Init.Period = 65535;
  htim20.Init.ClockDivision = TIM_CLOCKDIVISION_DIV1;
  htim20.Init.RepetitionCounter = 0;
  htim20.Init.AutoReloadPreload = TIM_AUTORELOAD_PRELOAD_DISABLE;
  if (HAL_TIM_Base_Init(&htim20) != HAL_OK)
  {
    Error_Handler();
  }
  if (HAL_TIM_PWM_Init(&htim20) != HAL_OK)
  {
    Error_Handler();
  }
  if (HAL_TIM_OC_Init(&htim20) != HAL_OK)
  {
    Error_Handler();
  }
  sSlaveConfig.SlaveMode = TIM_SLAVEMODE_TRIGGER;
  sSlaveConfig.InputTrigger = TIM_TS_ITR1;
  if (HAL_TIM_SlaveConfigSynchro(&htim20, &sSlaveConfig) != HAL_OK)
  {
    Error_Handler();
  }
  sMasterConfig.MasterOutputTrigger = TIM_TRGO_RESET;
  sMasterConfig.MasterOutputTrigger2 = TIM_TRGO2_RESET;
  sMasterConfig.MasterSlaveMode = TIM_MASTERSLAVEMODE_DISABLE;
  if (HAL_TIMEx_MasterConfigSynchronization(&htim20, &sMasterConfig) != HAL_OK)
  {
    Error_Handler();
  }
  sBreakInputConfig.Source = TIM_BREAKINPUTSOURCE_BKIN;
  sBreakInputConfig.Enable = TIM_BREAKINPUTSOURCE_ENABLE;
  sBreakInputConfig.Polarity = TIM_BREAKINPUTSOURCE_POLARITY_HIGH;
  if (HAL_TIMEx_ConfigBreakInput(&htim20, TIM_BREAKINPUT_BRK, &sBreakInputConfig) != HAL_OK)
  {
    Error_Handler();
  }
  if (HAL_TIMEx_ConfigBreakInput(&htim20, TIM_BREAKINPUT_BRK2, &sBreakInputConfig) != HAL_OK)
  {
    Error_Handler();
  }
  sConfigOC.OCMode = TIM_OCMODE_PWM1;
  sConfigOC.Pulse = 0;
  sConfigOC.OCPolarity = TIM_OCPOLARITY_HIGH;
  sConfigOC.OCNPolarity = TIM_OCNPOLARITY_HIGH;
  sConfigOC.OCFastMode = TIM_OCFAST_DISABLE;
  sConfigOC.OCIdleState = TIM_OCIDLESTATE_RESET;
  sConfigOC.OCNIdleState = TIM_OCNIDLESTATE_RESET;
  if (HAL_TIM_PWM_ConfigChannel(&htim20, &sConfigOC, TIM_CHANNEL_2) != HAL_OK)
  {
    Error_Handler();
  }
  sConfigOC.OCMode = TIM_OCMODE_TIMING;
  if (HAL_TIM_OC_ConfigChannel(&htim20, &sConfigOC, TIM_CHANNEL_3) != HAL_OK)
  {
    Error_Handler();
  }
  sBreakDeadTimeConfig.OffStateRunMode = TIM_OSSR_ENABLE;
  sBreakDeadTimeConfig.OffStateIDLEMode = TIM_OSSI_ENABLE;
  sBreakDeadTimeConfig.LockLevel = TIM_LOCKLEVEL_OFF;
  sBreakDeadTimeConfig.DeadTime = 0;
  sBreakDeadTimeConfig.BreakState = TIM_BREAK_ENABLE;
  sBreakDeadTimeConfig.BreakPolarity = TIM_BREAKPOLARITY_HIGH;
  sBreakDeadTimeConfig.BreakFilter = 0;
  sBreakDeadTimeConfig.BreakAFMode = TIM_BREAK_AFMODE_INPUT;
  sBreakDeadTimeConfig.Break2State = TIM_BREAK2_ENABLE;
  sBreakDeadTimeConfig.Break2Polarity = TIM_BREAK2POLARITY_HIGH;
  sBreakDeadTimeConfig.Break2Filter = 0;
  sBreakDeadTimeConfig.Break2AFMode = TIM_BREAK_AFMODE_INPUT;
  sBreakDeadTimeConfig.AutomaticOutput = TIM_AUTOMATICOUTPUT_DISABLE;
  if (HAL_TIMEx_ConfigBreakDeadTime(&htim20, &sBreakDeadTimeConfig) != HAL_OK)
  {
    Error_Handler();
  }
  HAL_TIM_MspPostInit(&htim20);

}

static void MX_USART1_UART_Init(void)
{

  huart1.Instance = USART1;
  huart1.Init.BaudRate = 115200;
  huart1.Init.WordLength = UART_WORDLENGTH_8B;
  huart1.Init.StopBits = UART_STOPBITS_1;
  huart1.Init.Parity = UART_PARITY_NONE;
  huart1.Init.Mode = UART_MODE_TX_RX;
  huart1.Init.HwFlowCtl = UART_HWCONTROL_NONE;
  huart1.Init.OverSampling = UART_OVERSAMPLING_16;
  huart1.Init.OneBitSampling = UART_ONE_BIT_SAMPLE_DISABLE;
  huart1.Init.ClockPrescaler = UART_PRESCALER_DIV1;
  huart1.AdvancedInit.AdvFeatureInit = UART_ADVFEATURE_NO_INIT;
  if (HAL_UART_Init(&huart1) != HAL_OK)
  {
    Error_Handler();
  }
  if (HAL_UARTEx_SetTxFifoThreshold(&huart1, UART_TXFIFO_THRESHOLD_1_8) != HAL_OK)
  {
    Error_Handler();
  }
  if (HAL_UARTEx_SetRxFifoThreshold(&huart1, UART_RXFIFO_THRESHOLD_1_8) != HAL_OK)
  {
    Error_Handler();
  }
  if (HAL_UARTEx_DisableFifoMode(&huart1) != HAL_OK)
  {
    Error_Handler();
  }

}

static void MX_GPIO_Init(void)
{
  GPIO_InitTypeDef GPIO_InitStruct = {0};

  /* GPIO Ports Clock Enable */
  __HAL_RCC_GPIOE_CLK_ENABLE();
  __HAL_RCC_GPIOC_CLK_ENABLE();
  __HAL_RCC_GPIOF_CLK_ENABLE();
  __HAL_RCC_GPIOG_CLK_ENABLE();
  __HAL_RCC_GPIOA_CLK_ENABLE();
  __HAL_RCC_GPIOB_CLK_ENABLE();
  __HAL_RCC_GPIOD_CLK_ENABLE();

  /*Configure GPIO pin Output Level */
  HAL_GPIO_WritePin(M2_ENABLE1_GPIO_GPIO_Port, M2_ENABLE1_GPIO_Pin, GPIO_PIN_RESET);

  /*Configure GPIO pin Output Level */
  HAL_GPIO_WritePin(GPIOF, GPIO_OUT_LED_GREEN_Pin|M1_ENABLE1_GPIO_Pin|M1_ENABLE2_GPIO_Pin|M2_ENABLE2_GPIO_Pin
                          |GPIO_OUT_INRUSH_Pin|GPIO_OUT_ID_ENABLE_Pin, GPIO_PIN_RESET);

  /*Configure GPIO pin Output Level */
  HAL_GPIO_WritePin(M3_ENABLE1_GPIO_GPIO_Port, M3_ENABLE1_GPIO_Pin, GPIO_PIN_RESET);

  /*Configure GPIO pin Output Level */
  HAL_GPIO_WritePin(GPIOG, GPIO_OUT_M2_ENABLE_Pin|GPIO_OUT_M1_ENABLE_Pin|GPIO_OUT_M1_BRAKE_Pin, GPIO_PIN_RESET);

  /*Configure GPIO pin Output Level */
  HAL_GPIO_WritePin(GPIOD, GPIO_OUT_M22_BRAKE_Pin|M3_ENABLE2_GPIO_Pin|GPIO_OUT_LED_YELLOW_Pin|GPIO_OUT_LED_RED_Pin, GPIO_PIN_RESET);

  /*Configure GPIO pin : M2_ENABLE1_GPIO_Pin */
  GPIO_InitStruct.Pin = M2_ENABLE1_GPIO_Pin;
  GPIO_InitStruct.Mode = GPIO_MODE_OUTPUT_PP;
  GPIO_InitStruct.Pull = GPIO_NOPULL;
  GPIO_InitStruct.Speed = GPIO_SPEED_FREQ_LOW;
  HAL_GPIO_Init(M2_ENABLE1_GPIO_GPIO_Port, &GPIO_InitStruct);

  /*Configure GPIO pin : PC13 */
  GPIO_InitStruct.Pin = GPIO_PIN_13;
  GPIO_InitStruct.Mode = GPIO_MODE_INPUT;
  GPIO_InitStruct.Pull = GPIO_PULLUP;
  HAL_GPIO_Init(GPIOC, &GPIO_InitStruct);

  /*Configure GPIO pins : GPIO_OUT_LED_GREEN_Pin M1_ENABLE1_GPIO_Pin M1_ENABLE2_GPIO_Pin M2_ENABLE2_GPIO_Pin
                           GPIO_OUT_INRUSH_Pin GPIO_OUT_ID_ENABLE_Pin */
  GPIO_InitStruct.Pin = GPIO_OUT_LED_GREEN_Pin|M1_ENABLE1_GPIO_Pin|M1_ENABLE2_GPIO_Pin|M2_ENABLE2_GPIO_Pin
                          |GPIO_OUT_INRUSH_Pin|GPIO_OUT_ID_ENABLE_Pin;
  GPIO_InitStruct.Mode = GPIO_MODE_OUTPUT_PP;
  GPIO_InitStruct.Pull = GPIO_NOPULL;
  GPIO_InitStruct.Speed = GPIO_SPEED_FREQ_LOW;
  HAL_GPIO_Init(GPIOF, &GPIO_InitStruct);

  /*Configure GPIO pin : BUTTON_RESET_Pin */
  GPIO_InitStruct.Pin = BUTTON_RESET_Pin;
  GPIO_InitStruct.Mode = GPIO_MODE_INPUT;
  GPIO_InitStruct.Pull = GPIO_NOPULL;
  HAL_GPIO_Init(BUTTON_RESET_GPIO_Port, &GPIO_InitStruct);

  /*Configure GPIO pins : PB0 PB1 */
  GPIO_InitStruct.Pin = GPIO_PIN_0|GPIO_PIN_1;
  GPIO_InitStruct.Mode = GPIO_MODE_ANALOG;
  GPIO_InitStruct.Pull = GPIO_NOPULL;
  HAL_GPIO_Init(GPIOB, &GPIO_InitStruct);

  /*Configure GPIO pin : M3_ENABLE1_GPIO_Pin */
  GPIO_InitStruct.Pin = M3_ENABLE1_GPIO_Pin;
  GPIO_InitStruct.Mode = GPIO_MODE_OUTPUT_PP;
  GPIO_InitStruct.Pull = GPIO_NOPULL;
  GPIO_InitStruct.Speed = GPIO_SPEED_FREQ_LOW;
  HAL_GPIO_Init(M3_ENABLE1_GPIO_GPIO_Port, &GPIO_InitStruct);

  /*Configure GPIO pins : GPIO_OUT_M2_ENABLE_Pin GPIO_OUT_M1_ENABLE_Pin GPIO_OUT_M1_BRAKE_Pin */
  GPIO_InitStruct.Pin = GPIO_OUT_M2_ENABLE_Pin|GPIO_OUT_M1_ENABLE_Pin|GPIO_OUT_M1_BRAKE_Pin;
  GPIO_InitStruct.Mode = GPIO_MODE_OUTPUT_PP;
  GPIO_InitStruct.Pull = GPIO_NOPULL;
  GPIO_InitStruct.Speed = GPIO_SPEED_FREQ_LOW;
  HAL_GPIO_Init(GPIOG, &GPIO_InitStruct);

  /*Configure GPIO pins : GPIO_OUT_M22_BRAKE_Pin M3_ENABLE2_GPIO_Pin GPIO_OUT_LED_YELLOW_Pin GPIO_OUT_LED_RED_Pin */
  GPIO_InitStruct.Pin = GPIO_OUT_M22_BRAKE_Pin|M3_ENABLE2_GPIO_Pin|GPIO_OUT_LED_YELLOW_Pin|GPIO_OUT_LED_RED_Pin;
  GPIO_InitStruct.Mode = GPIO_MODE_OUTPUT_PP;
  GPIO_InitStruct.Pull = GPIO_NOPULL;
  GPIO_InitStruct.Speed = GPIO_SPEED_FREQ_LOW;
  HAL_GPIO_Init(GPIOD, &GPIO_InitStruct);

}

void Error_Handler(void)
{
  __disable_irq();
  while (1)
  {
  }
}
